# STM32WBA54 register map
File version: 1.0
CPU: CM33 r0p1, little endian, MPU, FPU, 4 interrupt priority bits
Registers are 32-bit, read-write, reset 0x0 unless marked. A register's access mark holds for its fields unless they carry their own. Offsets are from the block's base; [hi:lo] are bit positions; {n}, {i} and the like mark numbered series.

## PWR — Power control
Base 0x46020800
Same registers: SEC_PWR 0x56020800
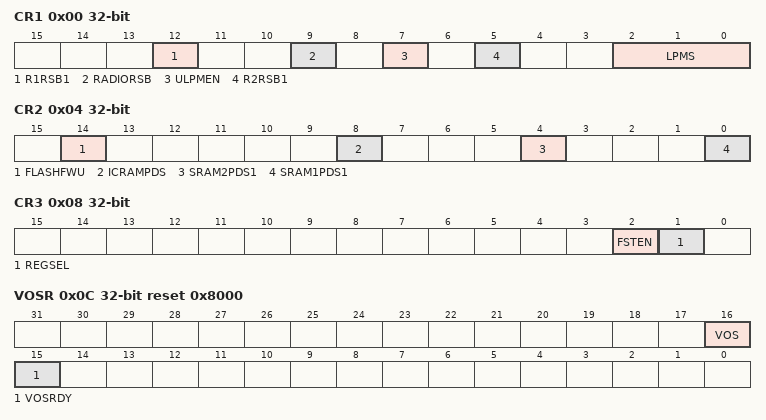
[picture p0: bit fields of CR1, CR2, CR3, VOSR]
0x00 CR1 — PWR control register 1
  [12] R1RSB1 — SRAM1 retention in Standby mode This bit is used to keep the SRAM1 content in Standby retention mode.
  [9] RADIORSB — 2.4 GHz RADIO SRAMs (RXTXRAM and Sequence RAM) and Sleep clock retention in Standby mode. This bit is used to keep the 2.4 GHz RADIO SRAMs content in Standby retention mode and the 2.4 GHz RADIO sleep timer counter operational.
  [7] ULPMEN — BOR0 ultra-low-power mode. This bit is used to reduce the consumption by configuring the BOR0 in discontinuous mode for Stop 1 and Standby modes. Discontinuous mode is only available when BOR levels 1 to 4 and PVD are disabled. Note: This bit must be set to reach the lowest power consumption in the low-power modes. Note: This bit must not be set together with autonomous peripherals using HSI16 as kernel clock. Note: When BOR level 1 to 4 or PVD is enabled continuous mode applies independent from ULPMEN.
  [5] R2RSB1 — SRAM2 retention in Standby mode This bit is used to keep the SRAM2 content in Standby retention mode.
  [2:0] LPMS — Low-power mode selection These bits select the low-power mode entered when the CPU enters the SleepDeep mode. 10x: Standby mode others reserved
0x04 CR2 — PWR control register 2
  [14] FLASHFWU — Flash memory fast wakeup from Stop modes (Stop 0, 1) This bit is used to obtain the best trade-off between low-power consumption and wakeup time when exiting the Stop 0 or Stop 1 modes. When this bit is set, the Flash memory remains in normal mode in Stop 0 and Stop 1 modes, which offers a faster startup time with higher consumption.
  [8] ICRAMPDS — ICACHE SRAM power-down in Stop modes (Stop 0, 1)
  [4] SRAM2PDS1 — SRAM2 power-down in Stop modes (Stop 0, 1) Note: The SRAM2 retention in Standby mode is controlled by R2RSB1 bit in PWR_CR1.
  [0] SRAM1PDS1 — SRAM1 power-down in Stop modes (Stop 0, 1) Note: The SRAM1 retention in Standby mode is controlled by R1RSB1 bit in PWR_CR1.
0x08 CR3 — PWR control register 3
  [2] FSTEN — Fast soft start
  [1] REGSEL — Regulator selection
0x0C VOSR access per field reset 0x8000 — PWR voltage scaling register
  [16] VOS rw — Voltage scaling range selection Set a and cleared by software. Cleared by hardware when entering Stop 1 mode. Access can be secured by RCC SYSCLKSEC. When secure, a non-secure read/write access is RAZ/WI. It does not generate an illegal access interrupt. This bit can be protected against unprivileged access when secure with PWR SPRIV or when non-secure with PWR NSPRIV.
  [15] VOSRDY ro — Ready bit for VsubCORE/sub voltage scaling output selection Set and cleared by hardware. When decreasing the voltage scaling range, VOSRDY must be one before increasing the SYSCLK frequency.
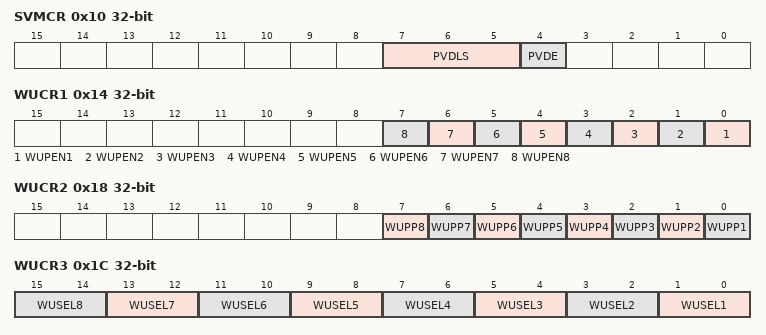
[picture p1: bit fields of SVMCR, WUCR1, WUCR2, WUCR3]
0x10 SVMCR — PWR supply voltage monitoring control register
  [7:5] PVDLS — Programmable voltage detector level selection These bits select the voltage threshold detected by the programmable voltage detector:
  [4] PVDE — Programmable voltage detector enable
0x14 WUCR1 — PWR wakeup control register 1
  [n-1] WUPEN{n} (n=1..8) — Wakeup and interrupt pin WKUP{n} enable Access can be secured by PWR WUP{n}SEC. When secure, a non-secure read/write access is RAZ/WI. It does not generate an illegal access interrupt. This bit can be protected against unprivileged access when secure with PWR SPRIV or when non-secure with PWR NSPRIV.
0x18 WUCR2 — PWR wakeup control register 2
  [n-1] WUPP{n} (n=2..8) — Wakeup pin WKUP{n} polarity This bit must be configured when WUPEN{n} = 0. Access can be secured by PWR WUP{n}SEC. When secure, a non-secure read/write access is RAZ/WI. It does not generate an illegal access interrupt. This bit can be protected against unprivileged access when secure with PWR SPRIV or when non-secure with PWR NSPRIV.
  [0] WUPP1 — Wakeup pin WKUP1 polarity. This bit must be configured when WUPEN1 = 0. Access can be secured by PWR WUP1SEC. When secure, a non-secure read/write access is RAZ/WI. It does not generate an illegal access interrupt. This bit can be protected against unprivileged access when secure with PWR SPRIV or when non-secure with PWR NSPRIV.
0x1C WUCR3 — PWR wakeup control register 3
  [2n-1:2n-2] WUSEL{n} (n=1..8) — Wakeup and interrupt pin WKUP{n} selection This field must be configured when WUPEN{n} = 0. Access can be secured by PWR WUP{n}SEC. When secure, a non-secure read/write access is RAZ/WI. It does not generate an illegal access interrupt. This bit can be protected against unprivileged access when secure with PWR SPRIV or when non-secure with PWR NSPRIV.
0x28 DBPR — PWR disable Backup domain register
  [0] DBP — Disable Backup domain write protection In reset state, all registers and SRAM in Backup domain are protected against parasitic write access. This bit must be set to enable the write access to these registers.
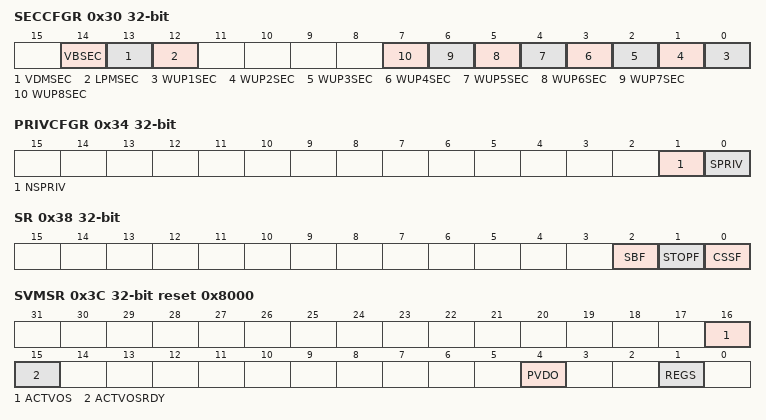
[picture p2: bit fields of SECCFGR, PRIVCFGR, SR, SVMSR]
0x30 SECCFGR — PWR security configuration register
  [14] VBSEC — Backup domain secure protection
  [13] VDMSEC — Voltage detection secure protection
  [12] LPMSEC — Low-power modes secure protection
  [n-1] WUP{n}SEC (n=1..8) — WUP{n} secure protection
0x34 PRIVCFGR — PWR privilege control register
  [1] NSPRIV — PWR non-secure functions privilege configuration This bit is set and reset by software. It can be written only by privileged access, secure or non-secure.
  [0] SPRIV — PWR secure functions privilege configuration This bit is set and reset by software. It can be written only by a secure privileged access.
0x38 SR access per field — PWR status register
  [2] SBF ro — Standby flag This bit is set by hardware when the device enters the Standby mode and the CPU restart from its reset vector. It's cleared by writing 1 to the CSSF bit, or by a power-on reset. It is not cleared by the system reset.
  [1] STOPF ro — Stop flag This bit is set by hardware when the device enters a Stop or Standby mode at the same time as the sysclk has been set by hardware to select HSI16. It's cleared by software by writing 1 to the CSSF bit and by hardware when SBF is set.
  [0] CSSF wo — Clear Stop and Standby flags Access can be secured by PWR LPMSEC. When secure, a non-secure read/write access is RAZ/WI. It does not generate an illegal access interrupt. This bit can be protected against unprivileged access when secure with PWR SPRIV or when non-secure with PWR NSPRIV. Writing 1 to this bit clears the STOPF and SBF flags.
0x3C SVMSR ro reset 0x8000 — PWR supply voltage monitoring status register
  [16] ACTVOS — VOS currently applied to VsubCORE/sub This field provides the last VOS value.
  [15] ACTVOSRDY — Voltage level ready for currently used VOS
  [4] PVDO — Programmable voltage detector output
  [1] REGS — Regulator selection
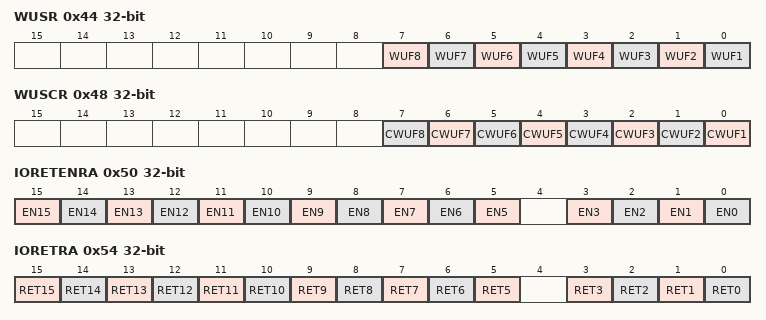
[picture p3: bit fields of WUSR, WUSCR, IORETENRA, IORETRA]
0x44 WUSR ro — PWR wakeup status register
  [7] WUF8 — Wakeup and interrupt pending flag 8 This bit is set when a wakeup event is detected on WKUP8 pin. This bit is cleared by writing 1 in the CWUF8 bit of PWR_WUSCR when WUSEL8 different 11, or by hardware when WUPEN8 = 0. When WUSEL8 = 11, this bit is cleared by hardware when all associated internal wakeup source are cleared. When WUSEL8 = 11, no WKUP interrupt is generated
  [6] WUF7 — Wakeup and interrupt pending flag 7 This bit is set when a wakeup event is detected on WKUP7 pin. This bit is cleared by writing 1 in the CWUF7 bit of PWR_WUSCR when WUSEL7 different 11, or by hardware when WUPEN7 = 0. When WUSEL7 = 11, this bit is cleared by hardware when all associated internal wakeup source are cleared. When WUSEL7 = 11, no WKUP interrupt is generated.
  [5] WUF6 — Wakeup and interrupt pending flag 6 This bit is set when a wakeup event is detected on WKUP6 pin. This bit is cleared by writing 1 in the CWUF6 bit of PWR_WUSCR when WUSEL6 different 11, or by hardware when WUPEN6 = 0. When WUSEL6 = 11, this bit is cleared by hardware when all associated internal wakeup source are cleared. When WUSEL6 = 11, no WKUP interrupt is generated
  [n-1] WUF{n} (n=1..5) — Wakeup and interrupt pending flag {n} This bit is set when a wakeup event is detected on WKUP{n} pin. This bit is cleared by writing 1 in the CWUF{n} bit of PWR_WUSCR or by hardware when WUPEN{n} = 0.
0x48 WUSCR wo — PWR wakeup status clear register
  [n-1] CWUF{n} (n=1..8) — Clear wakeup flag {n} Access can be secured by PWR WUP{n}SEC. When secure, a non-secure read/write access is RAZ/WI. It does not generate an illegal access interrupt. This bit can be protected against unprivileged access when secure with PWR SPRIV or when non-secure with PWR NSPRIV. Writing 1 to this bit clears the WUF{n} flag in PWR_WUSR.
0x50 IORETENRA — PWR port A Standby IO retention enable register
  [n] EN{n} (n=5..15) — Port A Standby GPIO retention enable Access can be secured by GPIOA SECy. When secure, a non-secure read/write access is RAZ/WI. It does not generate an illegal access interrupt. This bit can be protected against unprivileged access when secure with PWR SPRIV or when non-secure with PWR NSPRIV.
  [n] EN{n} (n=0..3) — Port A Standby GPIO retention enable Access can be protected by GPIOA SECy, privilege protection is controlled by PWR SPRIV or PWR NSPRIV. When set, each bit enables the Standby GPIO retention feature for PAy
0x54 IORETRA — PWR port A Standby IO retention status register
  [n] RET{n} (n=5..15) — Port A Standby GPIO retention active Access can be secured by GPIOA SECy. When secure, a non-secure read/write access is RAZ/WI. It does not generate an illegal access interrupt. This bit can be protected against unprivileged access when secure with PWR SPRIV or when non-secure with PWR NSPRIV.
  [n] RET{n} (n=0..3) — Port A Standby GPIO retention active Access can be protected by GPIOA SECy, privilege protection is controlled by PWR SPRIV or PWR NSPRIV.
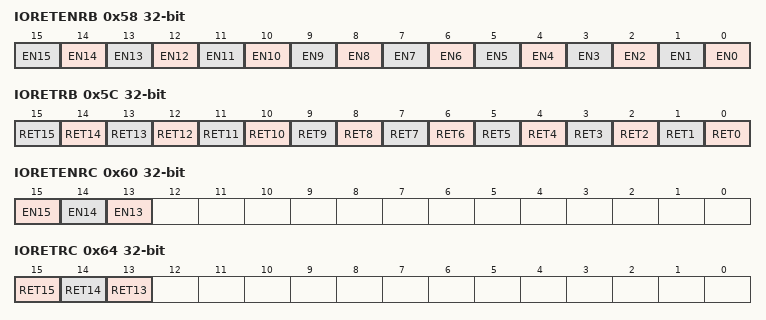
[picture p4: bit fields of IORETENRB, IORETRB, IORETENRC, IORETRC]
0x58 IORETENRB — PWR port B Standby IO retention enable register
  [n] EN{n} (n=0..15) — Port B Standby GPIO retention enable Access can be secured by GPIOB SECy. When secure, a non-secure read/write access is RAZ/WI. It does not generate an illegal access interrupt. This bit can be protected against unprivileged access when secure with PWR SPRIV or when non-secure with PWR NSPRIV.
0x5C IORETRB — PWR port B Standby IO retention status register
  [n] RET{n} (n=0..15) — Port B Standby GPIO retention active Access can be secured by GPIOB SECy. When secure, a non-secure read/write access is RAZ/WI. It does not generate an illegal access interrupt. This bit can be protected against unprivileged access when secure with PWR SPRIV or when non-secure with PWR NSPRIV.
0x60 IORETENRC — PWR port C Standby IO retention enable register
  [15] EN15 — Port C Standby GPIO retention enable Access can be secured by GPIOC SECy. When secure, a non-secure read/write access is RAZ/WI. It does not generate an illegal access interrupt. This bit can be protected against unprivileged access when secure with PWR SPRIV or when non-secure with PWR NSPRIV.
  [14] EN14 — Port C Standby GPIO retention enable Access can be secured by GPIOC SECy. When secure, a non-secure read/write access is RAZ/WI. It does not generate an illegal access interrupt. This bit can be protected against unprivileged access when secure with PWR SPRIV or when non-secure with PWR NSPRIV.
  [13] EN13 — Port C Standby GPIO retention enable Access can be secured by GPIOC SECy. When secure, a non-secure read/write access is RAZ/WI. It does not generate an illegal access interrupt. This bit can be protected against unprivileged access when secure with PWR SPRIV or when non-secure with PWR NSPRIV.
0x64 IORETRC — PWR port C Standby IO retention status register
  [15] RET15 — Port C Standby GPIO retention active Access can be secured by GPIOC SECy. When secure, a non-secure read/write access is RAZ/WI. It does not generate an illegal access interrupt. This bit can be protected against unprivileged access when secure with PWR SPRIV or when non-secure with PWR NSPRIV.
  [14] RET14 — Port C Standby GPIO retention active Access can be secured by GPIOC SECy. When secure, a non-secure read/write access is RAZ/WI. It does not generate an illegal access interrupt. This bit can be protected against unprivileged access when secure with PWR SPRIV or when non-secure with PWR NSPRIV.
  [13] RET13 — Port C Standby GPIO retention active Access can be secured by GPIOC SECy. When secure, a non-secure read/write access is RAZ/WI. It does not generate an illegal access interrupt. This bit can be protected against unprivileged access when secure with PWR SPRIV or when non-secure with PWR NSPRIV.
0x88 IORETENRH — PWR port H Standby IO retention enable register
  [3] EN3 — Port H Standby GPIO retention enable Access can be secured by GPIOH SEC3. When secure, a non-secure read/write access is RAZ/WI. It does not generate an illegal access interrupt. This bit can be protected against unprivileged access when secure with PWR SPRIV or when non-secure with PWR NSPRIV.
0x8C IORETRH — PWR port H Standby IO retention status register
  [3] RET3 — Port H Standby GPIO retention active Access can be secured by GPIOH SEC3. When secure, a non-secure read/write access is RAZ/WI. It does not generate an illegal access interrupt. This bit can be protected against unprivileged access when secure with PWR SPRIV or when non-secure with PWR NSPRIV.
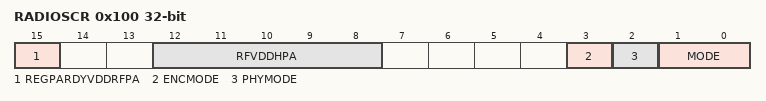
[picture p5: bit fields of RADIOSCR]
0x100 RADIOSCR ro — PWR 2.4 GHz RADIO status and control register
  [15] REGPARDYVDDRFPA — Ready bit for VsubDDHPA/sub voltage level when selecting VDDRFPA input. Note: REGPARDYVDDRFPA does not allow to detect correct VsubDDHPA/sub voltage level when request to lower the level.
  [12:8] RFVDDHPA — 2.4 GHz RADIO VDDHPA control word. Bits [3:0] see Table 81: PA output power table format for definition. Bit [4] rf_event.
  [3] ENCMODE — 2.4 GHz RADIO encryption function operating mode
  [2] PHYMODE — 2.4 GHz RADIO PHY operating mode
  [1:0] MODE — 2.4 GHz RADIO operating mode. 1x: 2.4 GHz RADIO active mode
